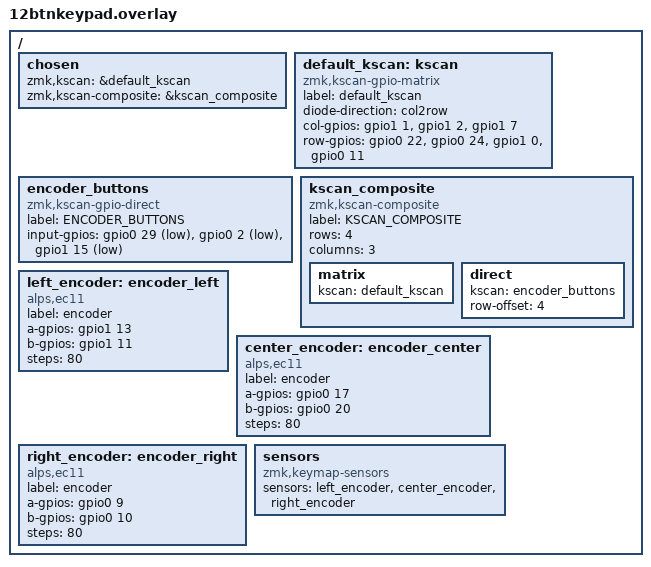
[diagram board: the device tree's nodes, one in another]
/ {
    chosen {
        zmk,kscan = &default_kscan;
        zmk,kscan-composite = &kscan_composite;
    };

    default_kscan: kscan {
        compatible = "zmk,kscan-gpio-matrix";
        label = "default_kscan";
        
        diode-direction = "col2row";
        
        col-gpios
            = <&gpio1 1 (GPIO_ACTIVE_HIGH | GPIO_PULL_UP)>
            , <&gpio1 2 (GPIO_ACTIVE_HIGH | GPIO_PULL_UP)>
            , <&gpio1 7 (GPIO_ACTIVE_HIGH | GPIO_PULL_UP)>
            ;
            
        row-gpios
            = <&gpio0 22 (GPIO_ACTIVE_HIGH | GPIO_PULL_DOWN)>
            , <&gpio0 24 (GPIO_ACTIVE_HIGH | GPIO_PULL_DOWN)>
            , <&gpio1 0 (GPIO_ACTIVE_HIGH | GPIO_PULL_DOWN)>
            , <&gpio0 11 (GPIO_ACTIVE_HIGH | GPIO_PULL_DOWN)>
            ;
    };

    encoder_buttons: encoder_buttons {
        compatible = "zmk,kscan-gpio-direct";
        label = "ENCODER_BUTTONS";

        input-gpios
            = <&gpio0 29 (GPIO_ACTIVE_LOW | GPIO_PULL_UP)>  // Left encoder button
            , <&gpio0 2 (GPIO_ACTIVE_LOW | GPIO_PULL_UP)>   // Center encoder button  
            , <&gpio1 15 (GPIO_ACTIVE_LOW | GPIO_PULL_UP)>  // Right encoder button
            ;
    };

    kscan_composite: kscan_composite {
        compatible = "zmk,kscan-composite";
        label = "KSCAN_COMPOSITE";
        rows = <4>;
        columns = <3>;

        matrix {
            kscan = <&default_kscan>;
        };

        direct {
            kscan = <&encoder_buttons>;
            row-offset = <4>; // Place after the matrix keys
        };
    };

    left_encoder: encoder_left {
        compatible = "alps,ec11";
        label = "encoder";
        a-gpios = <&gpio1 13 (GPIO_ACTIVE_HIGH | GPIO_PULL_UP)>;
        b-gpios = <&gpio1 11 (GPIO_ACTIVE_HIGH | GPIO_PULL_UP)>;
        steps = <80>;
        status = "okay";
    };
    
    center_encoder: encoder_center {
        compatible = "alps,ec11";
        label = "encoder";
        a-gpios = <&gpio0 17 (GPIO_ACTIVE_HIGH | GPIO_PULL_UP)>;
        b-gpios = <&gpio0 20 (GPIO_ACTIVE_HIGH | GPIO_PULL_UP)>;
        steps = <80>;
        status = "okay";
    };
    
    right_encoder: encoder_right {
        compatible = "alps,ec11";
        label = "encoder";
        a-gpios = <&gpio0 9 (GPIO_ACTIVE_HIGH | GPIO_PULL_UP)>;
        b-gpios = <&gpio0 10 (GPIO_ACTIVE_HIGH | GPIO_PULL_UP)>;
        steps = <80>;
        status = "okay";
    };

    sensors {
        compatible = "zmk,keymap-sensors";
        sensors = <&left_encoder &center_encoder &right_encoder>;
    };
};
